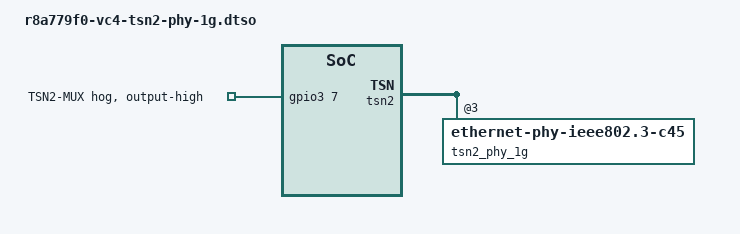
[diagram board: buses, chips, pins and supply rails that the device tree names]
/dts-v1/;
/plugin/;

#include <dt-bindings/gpio/gpio.h>

&gpio3 {
	tsn2-mux {
		gpio-hog;
		gpios = <7 GPIO_ACTIVE_HIGH>;
		output-high;
		line-name = "TSN2-MUX";
	};
};

&tsn2 {
	phy-mode = "sgmii";
	phy-handle = <&tsn2_phy_1g>;

	#address-cells = <1>;
	#size-cells = <0>;

	tsn2_phy_1g: ethernet-phy@3 {
		reg = <3>;
		compatible = "ethernet-phy-ieee802.3-c45";
		status = "okay";
	};
};
